# nrf5002 register map
Vendor: Nordic Semiconductor; Series: nRF50; File version: 1
CPU: CM0 r0p4, little endian, no MPU, no FPU, 2 interrupt priority bits, 32 interrupts
Registers are 32-bit, read-write, reset 0x0 unless marked. A register's access mark holds for its fields unless they carry their own. Offsets are from the block's base; [hi:lo] are bit positions; lines under a group give offsets from that group; {n}, {i} and the like mark numbered series; 'fields as' and 'values as' point back to an identical list.

## RAMBIST0 — The RamBist perform hardware accelerated RAM tests
Base 0x40025000
0x400 STATUS group — Unspecified
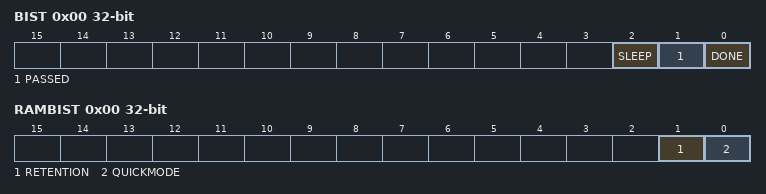
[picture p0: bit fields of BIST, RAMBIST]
  0x00 BIST ro — Status of the BIST
    [2] SLEEP — The RamBist is currently waiting for a RUNBIST handshake, see retention test protocol
    [1] PASSED — The RamBist passed, meaning all the compares in the pattern succeded
    [0] DONE — The RamBist is finished
  0x04 FAULTY ro — Which blocks are failing the test
    [15:0] BLOCKS — 0 if block has no miscompares, 1 if block has miscompares. Size and indices are equal to CLAMP.BLOCKS
0x500 RUN — Run the BIST engine, must be kept 1 until the BIST is finished
  [0] BIST — When 1, the RamBist runs
0x504 CONFIG group — Unspecified
  0x00 RAMBIST — Configuration of the RamBist itself. When none of the fields are set, it runs the standard production test BIST.
    [1] RETENTION — Runs the retention test protocol, does only exists if the connected RAMs require retention test
    [0] QUICKMODE — Runs a fast subset of the tests, intended for debug only
  0x04 RAM — Override of the RAM configuration
    [6:0] CONFIG — Depending on the RAM Vendor, this field is different. The reset value is also vendor dependent. (Noted as Vendor[width]: [Signal[width]=..].) TSMC0[4:0]: WTSEL[2:0], RTSEL[1:0]. TSMC1[1:0]: TSEL[1:0]. MobileSemi[6:0]: BTRIM[3:0], WM, RM, RWM.
  0x08 CLAMP — Clamp/Exclude certain blocks from the test
    [15:0] BLOCKS — Bit indexed, if an entry is 1, the block is not receiving stimuli, and excluded from the comparison. Parameterized with the number of RAM macros

## PCGCSLAVE_AMLI — PCGCSlave
Base 0x41000000
0x78 TRIGZEROPENALTY ro — Trigger zero penalty
  [0] TRIGGER
    1=Enable (Trigger zero penalty)
0x7C TRIGFULLPENALTY ro — Trigger full penalty
  [0] TRIGGER
    1=Enable (Trigger full penalty)
{0xC00+4i} PENALTY[{i}] (i=0..1) ro — Description collection: Penalty level for power/clock pair n
  [7:0] PENALTY — Penalty level
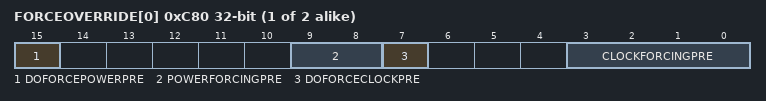
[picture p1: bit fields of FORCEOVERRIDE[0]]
{0xC80+4i} FORCEOVERRIDE[{i}] (i=0..1) ro — Description collection: Force override of power/clock pair n
  [15] DOFORCEPOWERPRE, [9:8] POWERFORCINGPRE, [7] DOFORCECLOCKPRE, [3:0] CLOCKFORCINGPRE

## PCGCMASTER0 — PCGC Master
Base 0x41001000
{0xE0+4i} SETPWRCONTHRESHOLDBASE[{i}] (i=0..2) ro — Description collection: Set power consumption threshold base for power source / regulator n
  [3:0] SETPWRCONTHRESHOLDBASE
{0x100+4i} SETPOWERCONSUMPTIONBASE[{i}] (i=0..1) ro — Description collection: Set power consumption base for power/clock pair n
  [3:0] POWERREQUIREMENT
0xC00 UNLOCKBACKDOORS ro
  [15:0] UNLOCKBACKDOORS — Write: 0x00009375 to lock/unlock backdoors Read: 0x00000001 if backdoors is enabled Read: 0x00000000 if backdoors is disabled
0xC04 ENABLEPOWERREGFORCE ro
  [2:0] ENABLEPOWERREGFORCE
0xC08 POWERREGFORCE ro — Force reg
  [2:0] POWERREGFORCEREG
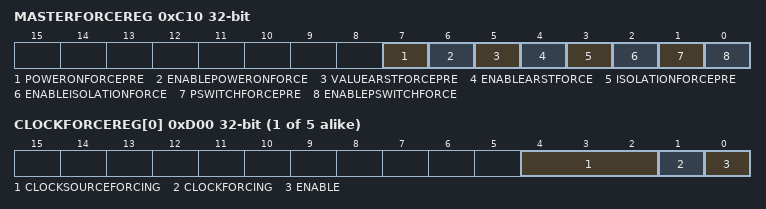
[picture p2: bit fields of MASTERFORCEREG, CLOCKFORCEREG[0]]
0xC10 MASTERFORCEREG ro — Force reg
  [7] POWERONFORCEPRE, [6] ENABLEPOWERONFORCE, [5] VALUEARSTFORCEPRE, [4] ENABLEARSTFORCE, [3] ISOLATIONFORCEPRE, [2] ENABLEISOLATIONFORCE, [1] PSWITCHFORCEPRE, [0] ENABLEPSWITCHFORCE
{0xD00+4i} CLOCKFORCEREG[{i}] (i=0..4) ro — Description collection: Force clock n
  [4:2] CLOCKSOURCEFORCING
  [1] CLOCKFORCING
  [0] ENABLE — Enable clock forcing

## POWER — Power control
Base 0x40000000; alternate view of CLOCK
0x78 TASKS_CONSTLAT wo — Enable constant latency mode When going to sleep: CPU is clock gated, but regulators, oscillators and clock tree is kept on.
  [0] TASKS_CONSTLAT
    1=Trigger task
0x7C TASKS_LOWPWR wo — Enable low power mode (variable latency) When going to sleep: Oscillators are switched off (if nothing else is requesting clocks). Regulators are switched off (if nothing else is requesting power).
  [0] TASKS_LOWPWR
    1=Trigger task
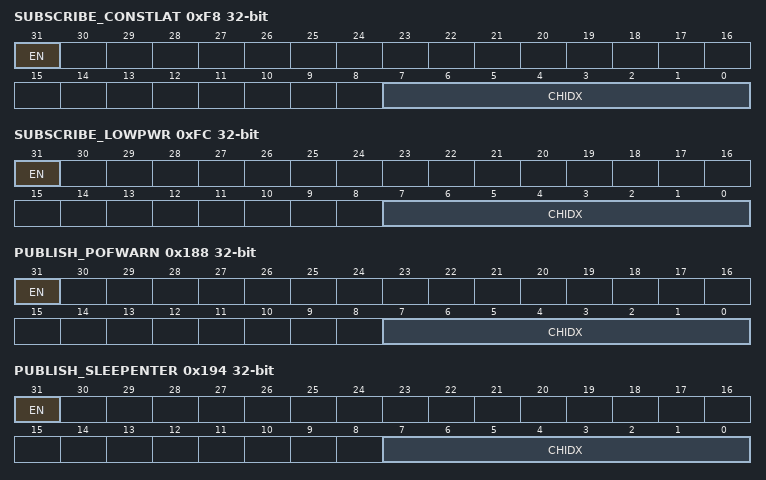
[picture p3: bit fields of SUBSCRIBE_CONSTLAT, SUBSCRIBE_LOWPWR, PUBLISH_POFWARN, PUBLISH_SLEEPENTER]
0xF8 SUBSCRIBE_CONSTLAT — Subscribe configuration for task CONSTLAT
  [31] EN
    0=Disabled (Disable subscription); 1=Enabled (Enable subscription)
  [7:0] CHIDX — DPPI channel that task CONSTLAT will subscribe to
0xFC SUBSCRIBE_LOWPWR — Subscribe configuration for task LOWPWR
  [31] EN
    values as SUBSCRIBE_CONSTLAT.EN
  [7:0] CHIDX — DPPI channel that task LOWPWR will subscribe to
0x108 EVENTS_POFWARN — Power failure warning
  [0] EVENTS_POFWARN
    0=NotGenerated (Event not generated); 1=Generated (Event generated)
0x114 EVENTS_SLEEPENTER — CPU entered WFI/WFE sleep
  [0] EVENTS_SLEEPENTER
    values as EVENTS_POFWARN.EVENTS_POFWARN
0x118 EVENTS_SLEEPEXIT — CPU exited WFI/WFE sleep
  [0] EVENTS_SLEEPEXIT
    values as EVENTS_POFWARN.EVENTS_POFWARN
0x188 PUBLISH_POFWARN — Publish configuration for event POFWARN
  [31] EN
    0=Disabled (Disable publishing); 1=Enabled (Enable publishing)
  [7:0] CHIDX — DPPI channel that event POFWARN will publish to
0x194 PUBLISH_SLEEPENTER — Publish configuration for event SLEEPENTER
  [31] EN
    values as PUBLISH_POFWARN.EN
  [7:0] CHIDX — DPPI channel that event SLEEPENTER will publish to
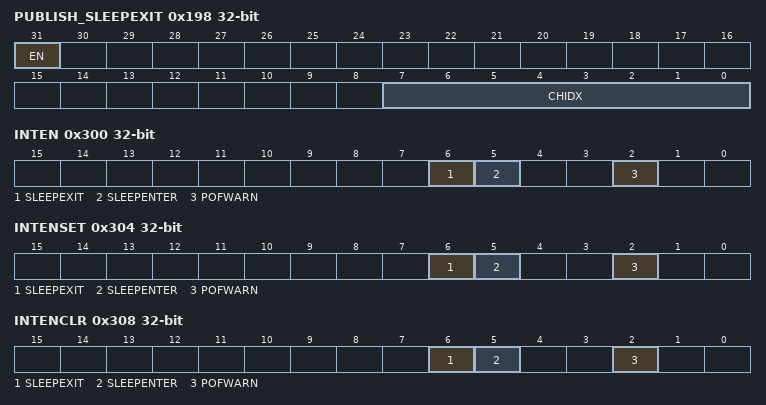
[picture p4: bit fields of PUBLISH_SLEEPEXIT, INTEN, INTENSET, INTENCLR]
0x198 PUBLISH_SLEEPEXIT — Publish configuration for event SLEEPEXIT
  [31] EN
    values as PUBLISH_POFWARN.EN
  [7:0] CHIDX — DPPI channel that event SLEEPEXIT will publish to
0x300 INTEN — Enable or disable interrupt
  [all] fields
    0=Disabled; 1=Enabled
  [6] SLEEPEXIT — Enable or disable interrupt for event SLEEPEXIT
  [5] SLEEPENTER — Enable or disable interrupt for event SLEEPENTER
  [2] POFWARN — Enable or disable interrupt for event POFWARN
0x304 INTENSET — Enable interrupt
  [all] fields
    on read: 0=Disabled (Read: Disabled); 1=Enabled (Read: Enabled) | on write: 1=Set (Enable)
  [6] SLEEPEXIT — Write '1' to enable interrupt for event SLEEPEXIT
  [5] SLEEPENTER — Write '1' to enable interrupt for event SLEEPENTER
  [2] POFWARN — Write '1' to enable interrupt for event POFWARN
0x308 INTENCLR — Disable interrupt
  [all] fields
    on read: 0=Disabled (Read: Disabled); 1=Enabled (Read: Enabled) | on write: 1=Clear (Disable)
  [6] SLEEPEXIT — Write '1' to disable interrupt for event SLEEPEXIT
  [5] SLEEPENTER — Write '1' to disable interrupt for event SLEEPENTER
  [2] POFWARN — Write '1' to disable interrupt for event POFWARN
{0x51C+4i} GPREGRET[{i}] (i=0..1) — Description collection: General purpose retention register
  [7:0] GPREGRET — General purpose retention register
